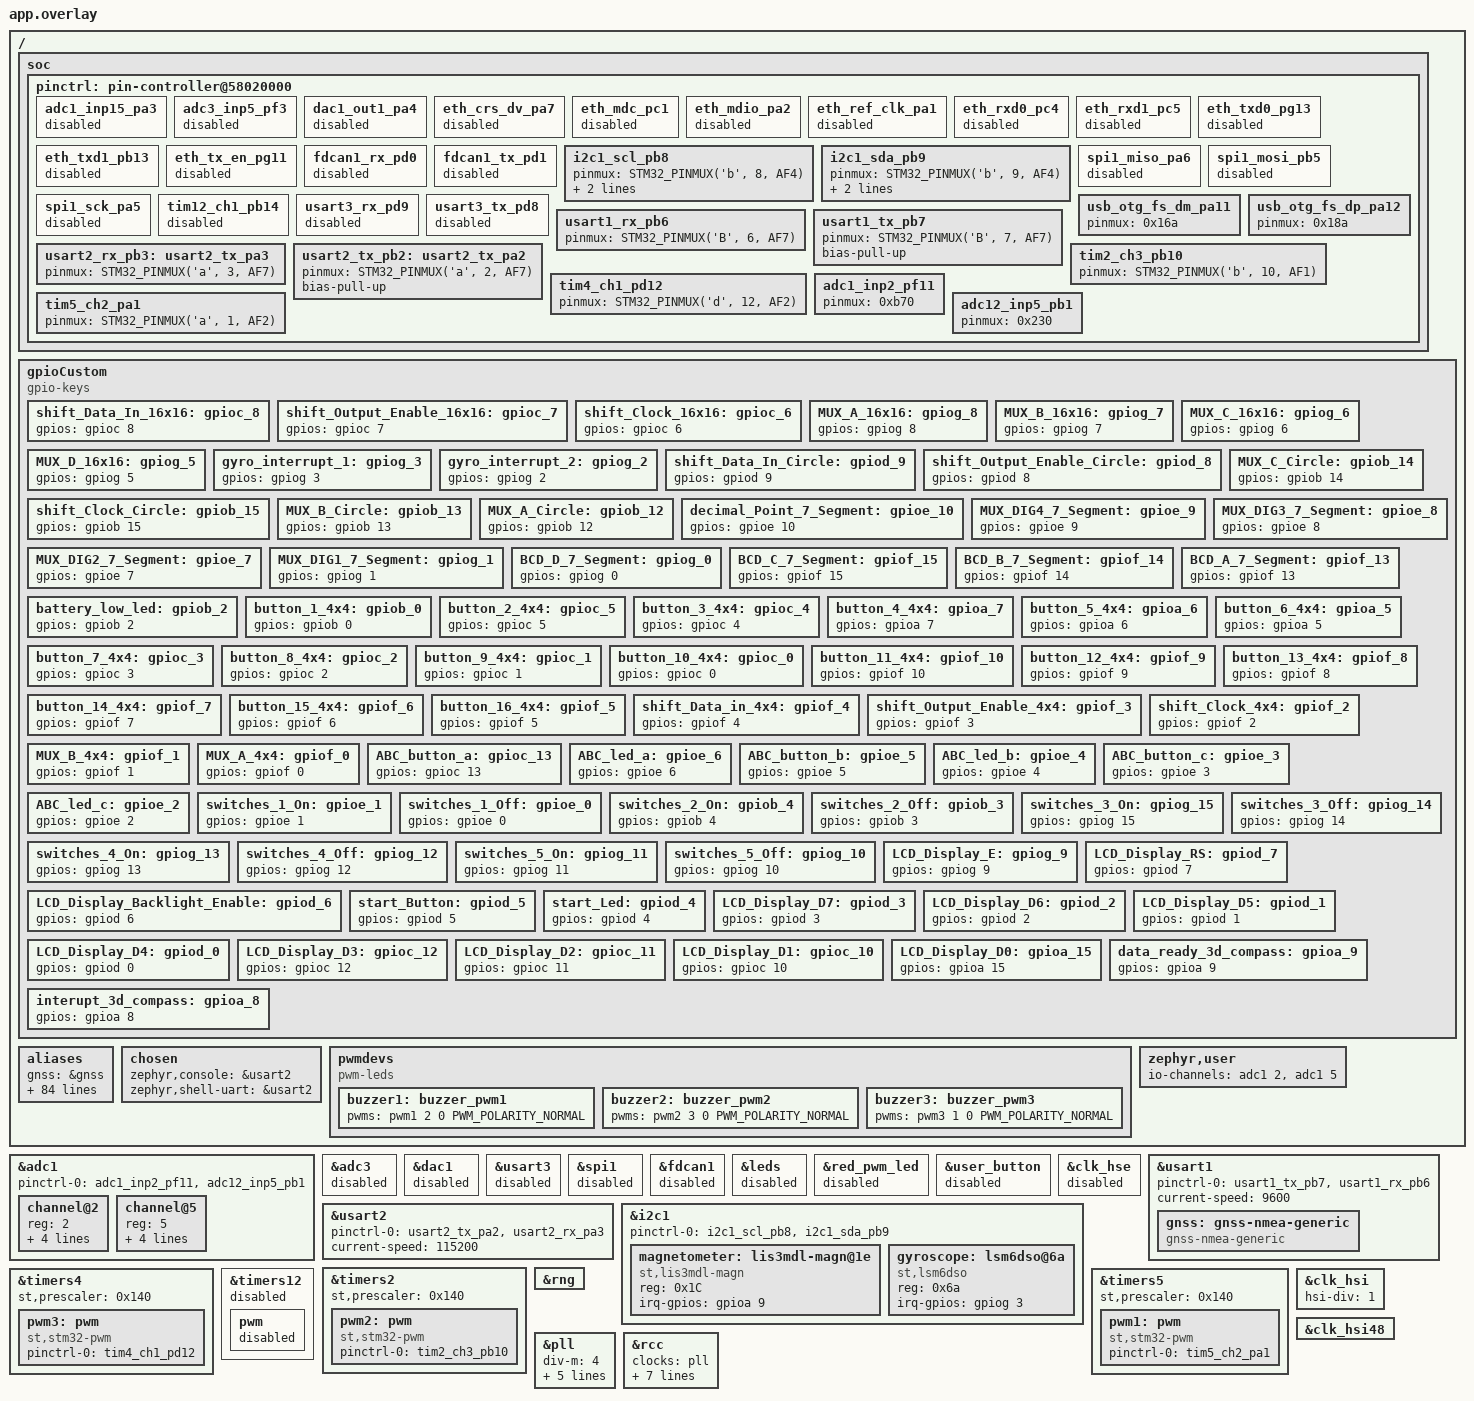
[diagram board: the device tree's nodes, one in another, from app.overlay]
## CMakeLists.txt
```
# SPDX-License-Identifier: Apache-2.0

cmake_minimum_required(VERSION 3.20.0)
find_package(Zephyr REQUIRED HINTS $ENV{ZEPHYR_BASE})
project(blinky)


# Gather source files using wildcards for src directory
file(GLOB SRC_HARDWARE_SOURCES 			"hardware/src/*.c")
file(GLOB SRC_HARDWARECONTROL_SOURCES 	"hardwareControl/src/*.c")
file(GLOB SRC_MAIN_SOURCES 				"main/src/*.c")
file(GLOB SRC_STATES_SOURCES 		"states/src/*.c")

# Add your source files
target_sources(app PRIVATE 
    ${SRC_HARDWARE_SOURCES}
	${SRC_HARDWARECONTROL_SOURCES}
	${SRC_MAIN_SOURCES}
	${SRC_STATES_SOURCES}
)

# Add include directories
target_include_directories(app PRIVATE
	${CMAKE_CURRENT_SOURCE_DIR}/hardware/inc
	${CMAKE_CURRENT_SOURCE_DIR}/hardwareControl/inc
	${CMAKE_CURRENT_SOURCE_DIR}/main/inc
	${CMAKE_CURRENT_SOURCE_DIR}/states/inc
)
```

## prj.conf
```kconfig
CONFIG_GPIO=y
CONFIG_DEBUG_OPTIMIZATIONS=y
CONFIG_SIZE_OPTIMIZATIONS=n
CONFIG_SPEED_OPTIMIZATIONS=n
CONFIG_ENTROPY_GENERATOR=y

CONFIG_STDOUT_CONSOLE=y
CONFIG_CBPRINTF_FP_SUPPORT=y

CONFIG_I2C=y
CONFIG_SENSOR=y
CONFIG_LSM6DSO_TRIGGER_NONE=y
CONFIG_LIS3MDL_ODR="155"

CONFIG_LSM6DSO=y
CONFIG_LSM6DSO_TRIGGER_NONE=y
CONFIG_PWM=y

CONFIG_GNSS=y
CONFIG_GNSS_SATELLITES=y

CONFIG_UART_INTERRUPT_DRIVEN=y
CONFIG_MODEM_MODULES=y

CONFIG_GNSS_SATELLITES=y

# CONFIG_ADC=y
```

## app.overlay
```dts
/ {
	soc {
		pinctrl: pin-controller@58020000 {
			//disable pins
			adc1_inp15_pa3: adc1_inp15_pa3 {
				status = "disabled";
			};
			adc3_inp5_pf3: adc3_inp5_pf3 {
				status = "disabled";
			};
			dac1_out1_pa4: dac1_out1_pa4 {
				status = "disabled";
			};
			eth_crs_dv_pa7: eth_crs_dv_pa7 {
				status = "disabled";
			};
			eth_mdc_pc1: eth_mdc_pc1 {
				status = "disabled";
			};
			eth_mdio_pa2: eth_mdio_pa2 {
				status = "disabled";
			};
			eth_ref_clk_pa1: eth_ref_clk_pa1 {
				status = "disabled";
			};
			eth_rxd0_pc4: eth_rxd0_pc4 {
				status = "disabled";
			};
			eth_rxd1_pc5: eth_rxd1_pc5 {
				status = "disabled";
			};
			eth_txd0_pg13: eth_txd0_pg13 {
				status = "disabled";
			};
			eth_txd1_pb13: eth_txd1_pb13 {
				status = "disabled";
			};
			eth_tx_en_pg11: eth_tx_en_pg11 {
				status = "disabled";
			};
			fdcan1_rx_pd0: fdcan1_rx_pd0 {
				status = "disabled";
			};
			fdcan1_tx_pd1: fdcan1_tx_pd1 {
				status = "disabled";
			};
			i2c1_scl_pb8: i2c1_scl_pb8 {
				status = "okay";
			};
			i2c1_sda_pb9: i2c1_sda_pb9 {
				status = "okay";
			};
			spi1_miso_pa6: spi1_miso_pa6 {
				status = "disabled";
			};
			spi1_mosi_pb5: spi1_mosi_pb5 {
				status = "disabled";
			};
			spi1_sck_pa5: spi1_sck_pa5 {
				status = "disabled";
			};
			tim12_ch1_pb14: tim12_ch1_pb14 {
				status = "disabled";
			};
			usart3_rx_pd9: usart3_rx_pd9 {
				status = "disabled";
			};
			usart3_tx_pd8: usart3_tx_pd8 {
				status = "disabled";
			};

			//enable and configure pins
			usb_otg_fs_dm_pa11: usb_otg_fs_dm_pa11 {
				pinmux = < 0x16a >;
				phandle = < 0x22 >;
				status = "okay";
			};
			usb_otg_fs_dp_pa12: usb_otg_fs_dp_pa12 {
				pinmux = < 0x18a >;
				phandle = < 0x23 >;
				status = "okay";
			};
			usart1_rx_pb6: usart1_rx_pb6 {
				pinmux = <STM32_PINMUX('B', 6, AF7)>;
				status = "okay";
			};
			usart1_tx_pb7: usart1_tx_pb7 {
				pinmux = <STM32_PINMUX('B', 7, AF7)>;
				bias-pull-up;
				status = "okay";
			};
			usart2_rx_pb3: usart2_tx_pa3 {
				pinmux = <STM32_PINMUX('a', 3, AF7)>;
				status = "okay";
			};
			usart2_tx_pb2: usart2_tx_pa2 {
				pinmux = <STM32_PINMUX('a', 2, AF7)>;
				bias-pull-up;
				status = "okay";
			};
			i2c1_scl_pb8: i2c1_scl_pb8 {
				pinmux = <STM32_PINMUX('b', 8, AF4)>;
				bias-pull-up;
				drive-open-drain;
				status = "okay";
				phandle = < 0xb >;
			};
			i2c1_sda_pb9: i2c1_sda_pb9 {
				pinmux = <STM32_PINMUX('b', 9, AF4)>;
				bias-pull-up;
				drive-open-drain;
				status = "okay";
				phandle = < 0xc >;
			};
			tim2_ch3_pb10: tim2_ch3_pb10{
				pinmux = <STM32_PINMUX('b', 10, AF1)>;
				status = "okay";
			};
			tim4_ch1_pd12: tim4_ch1_pd12{
				pinmux = <STM32_PINMUX('d', 12, AF2)>;
				status = "okay";
			};
			tim5_ch2_pa1: tim5_ch2_pa1{
				pinmux = <STM32_PINMUX('a', 1, AF2)>;
				status = "okay";
			};
			adc1_inp2_pf11: adc1_inp2_pf11 {
			pinmux = < 0xb70 >;
			status = "okay";
			};
			adc12_inp5_pb1: adc12_inp5_pb1 {
				pinmux = < 0x230 >;
				status = "okay";
			};
		};
	};

	gpioCustom {
		compatible = "gpio-keys";

		shift_Data_In_16x16: gpioc_8 {
			gpios = <&gpioc 8 GPIO_ACTIVE_HIGH>;
		};
		shift_Output_Enable_16x16: gpioc_7 {
			gpios = <&gpioc 7 GPIO_ACTIVE_HIGH>;
		};
		shift_Clock_16x16: gpioc_6 {
			gpios = <&gpioc 6 GPIO_ACTIVE_HIGH>;
		};
		MUX_A_16x16: gpiog_8 {
			gpios = <&gpiog 8 GPIO_ACTIVE_HIGH>;
		};
		MUX_B_16x16: gpiog_7 {
			gpios = <&gpiog 7 GPIO_ACTIVE_HIGH>;
		};
		MUX_C_16x16: gpiog_6 {
			gpios = <&gpiog 6 GPIO_ACTIVE_HIGH>;
		};
		MUX_D_16x16: gpiog_5 {
			gpios = <&gpiog 5 GPIO_ACTIVE_HIGH>;
		};
		gyro_interrupt_1: gpiog_3 {
			gpios = <&gpiog 3 GPIO_ACTIVE_HIGH>;
		};
		gyro_interrupt_2: gpiog_2 {
			gpios = <&gpiog 2 GPIO_ACTIVE_HIGH>;
		};
		shift_Data_In_Circle: gpiod_9 {
			gpios = <&gpiod 9 GPIO_ACTIVE_HIGH>;
		};
		shift_Output_Enable_Circle: gpiod_8 {
			gpios = <&gpiod 8 GPIO_ACTIVE_HIGH>;
		};
		shift_Clock_Circle: gpiob_15 {
			gpios = <&gpiob 15 GPIO_ACTIVE_HIGH>;
		};
		MUX_C_Circle: gpiob_14 {
			gpios = <&gpiob 14 GPIO_ACTIVE_HIGH>;
		};
		MUX_B_Circle: gpiob_13 {
			gpios = <&gpiob 13 GPIO_ACTIVE_HIGH>;
		};
		MUX_A_Circle: gpiob_12 {
			gpios = <&gpiob 12 GPIO_ACTIVE_HIGH>;
		};
		decimal_Point_7_Segment: gpioe_10 {
			gpios = <&gpioe 10 GPIO_ACTIVE_HIGH>;
		};
		MUX_DIG4_7_Segment: gpioe_9 {
			gpios = <&gpioe 9 GPIO_ACTIVE_HIGH>;
		};
		MUX_DIG3_7_Segment: gpioe_8 {
			gpios = <&gpioe 8 GPIO_ACTIVE_HIGH>;
		};
		MUX_DIG2_7_Segment: gpioe_7 {
			gpios = <&gpioe 7 GPIO_ACTIVE_HIGH>;
		};
		MUX_DIG1_7_Segment: gpiog_1 {
			gpios = <&gpiog 1 GPIO_ACTIVE_HIGH>;
		};
		BCD_D_7_Segment: gpiog_0 {
			gpios = <&gpiog 0 GPIO_ACTIVE_HIGH>;
		};
		BCD_C_7_Segment: gpiof_15 {
			gpios = <&gpiof 15 GPIO_ACTIVE_HIGH>;
		};
		BCD_B_7_Segment: gpiof_14 {
			gpios = <&gpiof 14 GPIO_ACTIVE_HIGH>;
		};
		BCD_A_7_Segment: gpiof_13 {
			gpios = <&gpiof 13 GPIO_ACTIVE_HIGH>;
		};
		battery_low_led: gpiob_2 {
			gpios = <&gpiob 2 GPIO_ACTIVE_HIGH>;
		};
		button_1_4x4: gpiob_0 {
			gpios = <&gpiob 0 GPIO_PULL_UP>;
		};
		button_2_4x4: gpioc_5 {
			gpios = <&gpioc 5 GPIO_PULL_UP>;
		};
		button_3_4x4: gpioc_4 {
			gpios = <&gpioc 4 GPIO_PULL_UP>;
		};
		button_4_4x4: gpioa_7 {
			gpios = <&gpioa 7 GPIO_PULL_UP>;
		};
		button_5_4x4: gpioa_6 {
			gpios = <&gpioa 6 GPIO_PULL_UP>;
		};
		button_6_4x4: gpioa_5 {
			gpios = <&gpioa 5 GPIO_PULL_UP>;
		};
		button_7_4x4: gpioc_3 {
			gpios = <&gpioc 3 GPIO_PULL_UP>;
		};
		button_8_4x4: gpioc_2 {
			gpios = <&gpioc 2 GPIO_PULL_UP>;
		};
		button_9_4x4: gpioc_1 {
			gpios = <&gpioc 1 GPIO_PULL_UP>;
		};
		button_10_4x4: gpioc_0 {
			gpios = <&gpioc 0 GPIO_PULL_UP>;
		};
		button_11_4x4: gpiof_10 {
			gpios = <&gpiof 10 GPIO_PULL_UP>;
		};
		button_12_4x4: gpiof_9 {
			gpios = <&gpiof 9 GPIO_PULL_UP>;
		};
		button_13_4x4: gpiof_8 {
			gpios = <&gpiof 8 GPIO_PULL_UP>;
		};
		button_14_4x4: gpiof_7 {
			gpios = <&gpiof 7 GPIO_PULL_UP>;
		};
		button_15_4x4: gpiof_6 {
			gpios = <&gpiof 6 GPIO_PULL_UP>;
		};
		button_16_4x4: gpiof_5 {
			gpios = <&gpiof 5 GPIO_PULL_UP>;
		};
		shift_Data_in_4x4: gpiof_4 {
			gpios = <&gpiof 4 GPIO_ACTIVE_HIGH>;
		};
		shift_Output_Enable_4x4: gpiof_3 {
			gpios = <&gpiof 3 GPIO_ACTIVE_HIGH>;
		};
		shift_Clock_4x4: gpiof_2 {
			gpios = <&gpiof 2 GPIO_ACTIVE_HIGH>;
		};
		MUX_B_4x4: gpiof_1 {
			gpios = <&gpiof 1 GPIO_ACTIVE_HIGH>;
		};
		MUX_A_4x4: gpiof_0 {
			gpios = <&gpiof 0 GPIO_ACTIVE_HIGH>;
		};
		ABC_button_a: gpioc_13 {
			gpios = <&gpioc 13 GPIO_PULL_UP>;
		};
		ABC_led_a: gpioe_6 {
			gpios = <&gpioe 6 GPIO_ACTIVE_HIGH>;
		};
		ABC_button_b: gpioe_5 {
			gpios = <&gpioe 5 GPIO_PULL_UP>;
		};
		ABC_led_b: gpioe_4 {
			gpios = <&gpioe 4 GPIO_ACTIVE_HIGH>;
		};
		ABC_button_c: gpioe_3 {
			gpios = <&gpioe 3 GPIO_PULL_UP>;
		};
		ABC_led_c: gpioe_2 {
			gpios = <&gpioe 2 GPIO_ACTIVE_HIGH>;
		};
		switches_1_On: gpioe_1 {
			gpios = <&gpioe 1 GPIO_PULL_UP>;
		};
		switches_1_Off: gpioe_0 {
			gpios = <&gpioe 0 GPIO_PULL_UP>;
		};
		switches_2_On: gpiob_4 {
			gpios = <&gpiob 4 GPIO_PULL_UP>;
		};
		switches_2_Off: gpiob_3 {
			gpios = <&gpiob 3 GPIO_PULL_UP>;
		};
		switches_3_On: gpiog_15 {
			gpios = <&gpiog 15 GPIO_PULL_UP>;
		};
		switches_3_Off: gpiog_14 {
			gpios = <&gpiog 14 GPIO_PULL_UP>;
		};
		switches_4_On: gpiog_13 {
			gpios = <&gpiog 13 GPIO_PULL_UP>;
		};
		switches_4_Off: gpiog_12 {
			gpios = <&gpiog 12 GPIO_PULL_UP>;
		};
		switches_5_On: gpiog_11 {
			gpios = <&gpiog 11 GPIO_PULL_UP>;
		};
		switches_5_Off: gpiog_10 {
			gpios = <&gpiog 10 GPIO_PULL_UP>;
		};
		LCD_Display_E: gpiog_9 {
			gpios = <&gpiog 9 GPIO_ACTIVE_HIGH>;
		};
		LCD_Display_RS: gpiod_7 {
			gpios = <&gpiod 7 GPIO_ACTIVE_HIGH>;
		};
		LCD_Display_Backlight_Enable: gpiod_6 {
			gpios = <&gpiod 6 GPIO_ACTIVE_HIGH>;
		};
		start_Button: gpiod_5 {
			gpios = <&gpiod 5 GPIO_PULL_UP>;
		};
		start_Led: gpiod_4 {
			gpios = <&gpiod 4 GPIO_ACTIVE_HIGH>;
		};
		LCD_Display_D7: gpiod_3 {
			gpios = <&gpiod 3 GPIO_ACTIVE_HIGH>;
		};
		LCD_Display_D6: gpiod_2 {
			gpios = <&gpiod 2 GPIO_ACTIVE_HIGH>;
		};
		LCD_Display_D5: gpiod_1 {
			gpios = <&gpiod 1 GPIO_ACTIVE_HIGH>;
		};
		LCD_Display_D4: gpiod_0 {
			gpios = <&gpiod 0 GPIO_ACTIVE_HIGH>;
		};
		LCD_Display_D3: gpioc_12 {
			gpios = <&gpioc 12 GPIO_ACTIVE_HIGH>;
		};
		LCD_Display_D2: gpioc_11 {
			gpios = <&gpioc 11 GPIO_ACTIVE_HIGH>;
		};
		LCD_Display_D1: gpioc_10 {
			gpios = <&gpioc 10 GPIO_ACTIVE_HIGH>;
		};
		LCD_Display_D0: gpioa_15 {
			gpios = <&gpioa 15 GPIO_ACTIVE_HIGH>;
		};
		data_ready_3d_compass: gpioa_9 {
			gpios = <&gpioa 9 GPIO_PULL_UP>;
		};
		interupt_3d_compass: gpioa_8 {
			gpios = <&gpioa 8 GPIO_PULL_UP>;
		};
	};

	aliases {
		gnss = &gnss;
		shiftdatain16x16 = &shift_Data_In_16x16;
		shiftenable16x16 = &shift_Output_Enable_16x16;
		shiftclock16x16 = &shift_Clock_16x16;
		muxa16x16 = &MUX_A_16x16;
		muxb16x16 = &MUX_B_16x16;
		muxc16x16 = &MUX_C_16x16;
		muxd16x16 = &MUX_D_16x16;
		gyrointerrupt1 = &gyro_interrupt_1;
		gyrointerrupt2 = &gyro_interrupt_2;
		shiftdataincircle = &shift_Data_In_Circle;
		shiftoutputenablecircle = &shift_Output_Enable_Circle;
		shiftclockcircle = &shift_Clock_Circle;
		muxacircle = &MUX_A_Circle;
		muxbcircle = &MUX_B_Circle;
		muxccircle = &MUX_C_Circle;
		decimalpoint7segment = &decimal_Point_7_Segment;
		muxdig17segment = &MUX_DIG1_7_Segment;
		muxdig27segment = &MUX_DIG2_7_Segment;
		muxdig37segment = &MUX_DIG3_7_Segment;
		muxdig47segment = &MUX_DIG4_7_Segment;
		bcdd7segment = &BCD_D_7_Segment;
		bcdc7segment = &BCD_C_7_Segment;
		bcdb7segment = &BCD_B_7_Segment;
		bcda7segment = &BCD_A_7_Segment;
		batterylowled = &battery_low_led;		
		button14x4 = &button_1_4x4;
		button24x4 = &button_2_4x4;
		button34x4 = &button_3_4x4;
		button44x4 = &button_4_4x4;
		button54x4 = &button_5_4x4;
		button64x4 = &button_6_4x4;
		button74x4 = &button_7_4x4;
		button84x4 = &button_8_4x4;
		button94x4 = &button_9_4x4;
		button104x4 = &button_10_4x4;
		button114x4 = &button_11_4x4;
		button124x4 = &button_12_4x4;
		button134x4 = &button_13_4x4;
		button144x4 = &button_14_4x4;
		button154x4 = &button_15_4x4;
		button164x4 = &button_16_4x4;
		shiftdatain4x4 = &shift_Data_in_4x4;
		shiftoutputenable4x4 = &shift_Output_Enable_4x4;
		shiftclock4x4 = &shift_Clock_4x4;
		muxa4x4 = &MUX_A_4x4;
		muxb4x4 = &MUX_B_4x4;
		abcbuttona = &ABC_button_a;
		abcleda = &ABC_led_a;
		abcbuttonb = &ABC_button_b;
		abcledb = &ABC_led_b;
		abcbuttonc = &ABC_button_c;
		abcledc = &ABC_led_c;
		switches1on = &switches_1_On;
		switches1off = &switches_1_Off;
		switches2on = &switches_2_On;
		switches2off = &switches_2_Off;
		switches3on = &switches_3_On;
		switches3off = &switches_3_Off;
		switches4on = &switches_4_On;
		switches4off = &switches_4_Off;
		switches5on = &switches_5_On;
		switches5off = &switches_5_Off;
		lcddisplaye = &LCD_Display_E;
		lcddisplayrs = &LCD_Display_RS;
		lcddisplaybacklightenable = &LCD_Display_Backlight_Enable;
		startbutton = &start_Button;
		startled = &start_Led;
		lcddisplayd7 = &LCD_Display_D7;
		lcddisplayd6 = &LCD_Display_D6;
		lcddisplayd5 = &LCD_Display_D5;
		lcddisplayd4 = &LCD_Display_D4;
		lcddisplayd3 = &LCD_Display_D3;
		lcddisplayd2 = &LCD_Display_D2;
		lcddisplayd1 = &LCD_Display_D1;
		lcddisplayd0 = &LCD_Display_D0;
		buzzer1=&buzzer1;
		buzzer2=&buzzer2;
		buzzer3=&buzzer3;
		3dcompassdataready = &data_ready_3d_compass;
		3dcompassintterupt = &interupt_3d_compass;
		magnetometer=&magnetometer;
		gyroscope=&gyroscope;
	};

	 chosen {
		zephyr,console = &usart2;
		zephyr,shell-uart = &usart2;
	};

	pwmdevs {
		compatible = "pwm-leds";
		status = "okay";
		buzzer1: buzzer_pwm1 {
			pwms = 	<&pwm1 2 0 PWM_POLARITY_NORMAL>;
			status = "okay";
		};
		buzzer2: buzzer_pwm2 {
			pwms = 	<&pwm2 3 0 PWM_POLARITY_NORMAL>;
			status = "okay";
		};
		buzzer3: buzzer_pwm3 {
			pwms = 	<&pwm3 1 0 PWM_POLARITY_NORMAL>;
			status = "okay";
		};
	};
};

/ {
	zephyr,user {
		/* adjust channel number according to pinmux in board.dts */
		io-channels = <&adc1 2>, <&adc1 5>;
	};
};

&adc1{
		status = "okay";
		pinctrl-0 = < &adc1_inp2_pf11 &adc12_inp5_pb1>;
		

		#address-cells = <1>;
		#size-cells = <0>;

		channel@2 {
			reg = <2>;
			zephyr,gain = "ADC_GAIN_1";
			zephyr,reference = "ADC_REF_INTERNAL";
			zephyr,acquisition-time = <ADC_ACQ_TIME_DEFAULT>;
			zephyr,resolution = <12>;
		};

		channel@5 {
			reg = <5>;
			zephyr,gain = "ADC_GAIN_1";
			zephyr,reference = "ADC_REF_INTERNAL";
			zephyr,acquisition-time = <ADC_ACQ_TIME_DEFAULT>;
			zephyr,resolution = <12>;
		};
	
};

//disable unused


&adc3{
		status = "disabled";
};

&dac1{
		status = "disabled";
};

&usart3 {
		status = "disabled";
};

&spi1 {
		status = "disabled";
};

&fdcan1{
		status = "disabled";
};

&leds{
		status = "disabled";
};

&red_pwm_led {
		status = "okay";
};

&user_button {
		status = "disabled";
};

&clk_hse {
		status = "disabled";
};

//enable used

&usart1 {
		pinctrl-0 = < &usart1_tx_pb7 &usart1_rx_pb6 >;
		pinctrl-names = "default";
        current-speed = <9600>;
        status = "okay";
        gnss: gnss-nmea-generic {
                compatible = "gnss-nmea-generic";
        };
};

&usart2 {
		pinctrl-0 = < &usart2_tx_pa2 &usart2_rx_pa3 >;
		pinctrl-names = "default";
        current-speed = <115200>;
        status = "okay";
};


&i2c1{
		status = "okay";
		pinctrl-0 = < &i2c1_scl_pb8 &i2c1_sda_pb9 >;

		magnetometer: lis3mdl-magn@1e {
			compatible = "st,lis3mdl-magn";
			reg = <0x1C>;
			irq-gpios = <&gpioa 9 GPIO_ACTIVE_HIGH>;
		};

		gyroscope: lsm6dso@6a {
			compatible = "st,lsm6dso";
			reg = <0x6a>;
			irq-gpios = <&gpiog 3 GPIO_ACTIVE_HIGH>; //the selected pin is wrong. check schematic
		};
};

// &timers1{
// 	status = "okay";
// 	st,prescaler = < 0x140 >; 
// 	pwm1: pwm{
// 		compatible = "st,stm32-pwm";
// 		status = "okay";
// 		#pwm-cells = < 0x3 >;
// 		pinctrl-0 = < &tim1_ch1_pe9>;
// 		pinctrl-names = "default";
// 	};
// };

&timers2{
	status = "okay";
	st,prescaler = < 0x140 >; 
	pwm2: pwm{
		compatible = "st,stm32-pwm";
		status = "okay";
		#pwm-cells = < 0x3 >;
		pinctrl-0 = < &tim2_ch3_pb10>;
		pinctrl-names = "default";
	};
};

&timers4{
	status = "okay";
	st,prescaler = < 0x140 >; 
	pwm3: pwm{
		compatible = "st,stm32-pwm";
		status = "okay";
		#pwm-cells = < 0x3 >;
		pinctrl-0 = < &tim4_ch1_pd12>;
		pinctrl-names = "default";
	};
};

&timers5{
	status = "okay";
	st,prescaler = < 0x140 >; 
	pwm1: pwm{
		compatible = "st,stm32-pwm";
		status = "okay";
		#pwm-cells = < 0x3 >;
		pinctrl-0 = < &tim5_ch2_pa1>;
		pinctrl-names = "default";
	};
};

&timers12{
	status = "disabled";
	pwm{
		status = "disabled";
	};
};

&clk_hsi{
	status = "okay";
	hsi-div = <1>;
};

&clk_hsi48{
	status = "okay";
};

&rng{
	status = "okay";
};

&pll {
	div-m = <4>;
	mul-n = <40>;
	div-p = <2>;
	div-q = <3>;
	div-r = <2>;
	clocks = <&clk_hsi>;
	status = "okay";
};

&rcc {
	clocks = <&pll>;
	clock-frequency = <DT_FREQ_M(320)>;
	d1cpre = < 0x1 >;
	hpre = < 0x2 >;
	d1ppre = < 0x2 >;
	d2ppre1 = < 0x2 >;
	d2ppre2 = < 0x2 >;
	d3ppre = < 0x2 >;
};

&red_pwm_led{
	status = "disabled";
};
```

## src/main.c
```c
/*
 * Copyright (c) 2023 Trackunit Corporation
 *
 * SPDX-License-Identifier: Apache-2.0
 */
#include "statemachine.h"
#include <stdio.h>

int main(void)
{
	startStatemachine();
	printf("A thing\n");
	return 0;
}
```

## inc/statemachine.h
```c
void startStatemachine();
```

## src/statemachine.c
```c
// Includes: own header file, hardware headers, minigame headers, framework headers, system headers (sorted alpabetically)
#include "statemachine.h"

#include "buttonMatrix.h"
#include "buzzers.h"
#include "genericGpio.h"
#include "gps.h"
#include "gyroCompass.h"
#include "ledCircle.h"
#include "ledMatrix.h"
#include "potmeter.h"
#include "sevenSegment.h"

#include "minigame1.h"
#include "minigame2.h"
#include "minigame3.h"
#include "minigame4.h"
#include "minigame5.h"
#include "minigame6.h"
#include "minigame7.h"
#include "minigame8.h"
#include "minigame9.h"
#include "minigame10.h"

#include <zephyr/device.h>
#include <zephyr/drivers/gpio.h>
#include <zephyr/kernel.h>
#include <zephyr/sys/util.h>
#include <zephyr/sys/printk.h>

#include <stdio.h>


// The stack size of all threads
#define STACKSIZE 1024

// Thread priority values (lower value is higher priority)
#define TSTARTBUTTON_PRIORITY 4
#define TGYRO_PRIORITY 4
#define TGPS_PRIORITY 4
#define TBTNMATRIX_OUT_PRIORITY 7
#define TBTNMATRIX_IN_PRIORITY 4
#define TSWITCHES_PRIORITY 4
#define TPOTMETER_PRIORITY 4
#define TBUZZERS_PRIORITY 7
#define TLEDMATRIX_PRIORITY 7
#define TLEDCIRCLE_PRIORITY 7
#define TSEVENSEG_PRIORITY 7
#define TABCBTN_PRIORITY 4

// Thread IDs
extern const k_tid_t tstartbutton_id;
extern const k_tid_t tgyro_id;
extern const k_tid_t tgps_id;
extern const k_tid_t tbtnmatrix_out_id;
extern const k_tid_t tbtnmatrix_in_id;
extern const k_tid_t tswitches_id;
extern const k_tid_t tpotmeter_id;
extern const k_tid_t tbuzzers_id;
extern const k_tid_t tledmatrix_id;
extern const k_tid_t tledcircle_id;
extern const k_tid_t tsevenseg_id;
extern const k_tid_t tabcbtn_id;

// Setup state machine
struct state;
typedef void state_fn(struct state *);

struct state {
	state_fn *next;
	int i;
};

state_fn init_state, walk_state, mg1_state, mg2_state, mg3_state, mg4_state, mg5_state, mg6_state, mg7_state, mg8_state, mg9_state, mg10_state, exit_state;

// State functions
void init_state(struct state *state) {
	printf("Initialization\n");

	// Disable all io threads
	k_thread_suspend(tstartbutton_id);
	k_thread_suspend(tgyro_id);
	k_thread_suspend(tgps_id);
	k_thread_suspend(tbtnmatrix_out_id);
	k_thread_suspend(tbtnmatrix_in_id);
	k_thread_suspend(tswitches_id);
	k_thread_suspend(tpotmeter_id);
	k_thread_suspend(tbuzzers_id);
	k_thread_suspend(tledmatrix_id);
	k_thread_suspend(tledcircle_id);
	k_thread_suspend(tsevenseg_id);
	k_thread_suspend(tabcbtn_id);

	state->next = walk_state;
}

void walk_state(struct state *state) {
	printf("Walking\n");
	state->next = mg1_state;
}

void mg1_state(struct state *state) { // Makes use of button and led
	// Initialise state, enable and disable corresponding threads
	printf("Minigame 1\n");

	// Enable required threads
	//k_thread_resume(tstartbutton_id);
	//k_thread_resume(tgyro_id);
	//k_thread_resume(tledmatrix_id);
	/* Temporarily enabling GPS in this mingame so I can test the driver **************************************/
	k_thread_resume(tgps_id);

	int ret = playMg1();

	// Disable required threads after finishing
	k_thread_suspend(tstartbutton_id);
	k_thread_suspend(tgyro_id);
	k_thread_suspend(tledmatrix_id);
	/* Temporarily enabling GPS in this mingame so I can test the driver **************************************/
	k_thread_suspend(tgps_id);

	state->next = mg2_state;
}

void mg2_state(struct state *state) { // Makes use of gyro and buzzer
	printf("Minigame 2\n");

	// Enable required threads
	k_thread_resume(tstartbutton_id);
	k_thread_resume(tbtnmatrix_in_id);
	k_thread_resume(tbtnmatrix_out_id);
	k_thread_resume(tbuzzers_id);

	int ret = playMg2();

	// Disable required threads after finishing
	k_thread_suspend(tstartbutton_id);
	k_thread_suspend(tbtnmatrix_in_id);
	k_thread_suspend(tbtnmatrix_out_id);
	k_thread_suspend(tbuzzers_id);

	state->next = mg3_state;
}

void mg3_state(struct state *state) { // Makes use of gyro and buzzer
	printf("Minigame 3\n");

	// Enable required threads
	k_thread_resume(tstartbutton_id);
	k_thread_resume(tbtnmatrix_in_id);
	k_thread_resume(tbtnmatrix_out_id);
	k_thread_resume(tbuzzers_id);

	int ret = playMg3();

	// Disable required threads after finishing
	k_thread_suspend(tstartbutton_id);
	k_thread_suspend(tbtnmatrix_in_id);
	k_thread_suspend(tbtnmatrix_out_id);
	k_thread_suspend(tbuzzers_id);

	state->next = mg4_state;
}

void mg4_state(struct state *state) { // Makes use of gyro and buzzer
	printf("Minigame 4\n");

	// Enable required threads
	k_thread_resume(tstartbutton_id);
	k_thread_resume(tbuzzers_id);
	k_thread_resume(tabcbtn_id);

	int ret = playMg4();

	// Disable required threads after finishing
	k_thread_suspend(tstartbutton_id);
	k_thread_suspend(tbuzzers_id);
	k_thread_suspend(tabcbtn_id);

	state->next = mg5_state;
}

void mg5_state(struct state *state) { // Makes use of gyro and buzzer
	printf("Minigame 5\n");

	// Enable required threads
	k_thread_resume(tstartbutton_id);
	k_thread_resume(tbtnmatrix_in_id);
	k_thread_resume(tbtnmatrix_out_id);

	int ret = playMg5();

	// Disable required threads after finishing
	k_thread_suspend(tstartbutton_id);
	k_thread_suspend(tbtnmatrix_in_id);
	k_thread_suspend(tbtnmatrix_out_id);

	state->next = mg6_state;
}

void mg6_state(struct state *state) { // Makes use of gyro and buzzer
	printf("Minigame 6\n");

	// Enable required threads
	k_thread_resume(tstartbutton_id);
	k_thread_resume(tsevenseg_id);
	k_thread_resume(tabcbtn_id);

	int ret = playMg6();

	// Disable required threads after finishing
	k_thread_suspend(tstartbutton_id);
	k_thread_suspend(tsevenseg_id);
	k_thread_suspend(tabcbtn_id);;

	state->next = mg7_state;
}

void mg7_state(struct state *state) { // Makes use of gyro and buzzer
	printf("Minigame 7\n");

	// Enable required threads
	k_thread_resume(tstartbutton_id);
	k_thread_resume(tgyro_id);
	k_thread_resume(tledmatrix_id);

	int ret = playMg7();

	// Disable required threads after finishing
	k_thread_suspend(tstartbutton_id);
	k_thread_suspend(tgyro_id);
	k_thread_suspend(tledmatrix_id);

	state->next = mg8_state;
}

void mg8_state(struct state *state) { // Makes use of gyro and buzzer
	printf("Minigame 8\n");

	// Enable required threads
	k_thread_resume(tstartbutton_id);
	k_thread_resume(tledmatrix_id);
	k_thread_resume(tabcbtn_id);

	int ret = playMg8();

	// Disable required threads after finishing
	k_thread_suspend(tstartbutton_id);
	k_thread_suspend(tledmatrix_id);
	k_thread_suspend(tabcbtn_id);

	state->next = mg9_state;
}

void mg9_state(struct state *state) { // Makes use of gyro and buzzer
	printf("Minigame 9\n");

	// Enable required threads
	k_thread_resume(tstartbutton_id);
	k_thread_resume(tswitches_id);

	int ret = playMg9();

	// Disable required threads after finishing
	k_thread_suspend(tstartbutton_id);
	k_thread_suspend(tswitches_id);

	state->next = mg10_state;
}

void mg10_state(struct state *state) { // Makes use of gyro and buzzer
	printf("Minigame 10\n");

	// Enable required threads
	k_thread_resume(tstartbutton_id);
	k_thread_resume(tbtnmatrix_in_id);
	k_thread_resume(tswitches_id);
	k_thread_resume(tpotmeter_id);
	k_thread_resume(tabcbtn_id);

	int ret = playMg10();

	// Disable required threads after finishing
	k_thread_suspend(tstartbutton_id);
	k_thread_suspend(tbtnmatrix_in_id);
	k_thread_suspend(tswitches_id);
	k_thread_suspend(tpotmeter_id);
	k_thread_suspend(tabcbtn_id);

	state->next = exit_state;
}

void exit_state(struct state *state) {
	printf("Exit state");
	k_thread_suspend(tstartbutton_id);
	k_thread_suspend(tgyro_id);
	k_thread_suspend(tgps_id);
	k_thread_suspend(tbtnmatrix_out_id);
	k_thread_suspend(tbtnmatrix_in_id);
	k_thread_suspend(tswitches_id);
	k_thread_suspend(tpotmeter_id);
	k_thread_suspend(tbuzzers_id);
	k_thread_suspend(tledmatrix_id);
	k_thread_suspend(tledcircle_id);
	k_thread_suspend(tsevenseg_id);
	k_thread_suspend(tabcbtn_id);
	state->next = 0;
}

void startStatemachine() {
	struct state state = {init_state, 0};
	while (state.next) state.next(&state);
}

// Define the threads
// Input threads
K_THREAD_DEFINE(tstartbutton_id, STACKSIZE, tstartbutton, NULL, NULL, NULL, TSTARTBUTTON_PRIORITY, 0,0);
K_THREAD_DEFINE(tgyro_id, STACKSIZE, tgyro, NULL, NULL, NULL, TGYRO_PRIORITY, 0,0);
K_THREAD_DEFINE(tbtnmatrix_in_id, STACKSIZE, tbtnmatrix_in, NULL, NULL, NULL, TBTNMATRIX_IN_PRIORITY, 0, 0);
K_THREAD_DEFINE(tswitches_id, STACKSIZE, tswitches, NULL, NULL, NULL, TSWITCHES_PRIORITY, 0, 0);
K_THREAD_DEFINE(tpotmeter_id, STACKSIZE, tpotmeter, NULL, NULL, NULL, TPOTMETER_PRIORITY, 0, 0);
K_THREAD_DEFINE(tabcbtn_id, STACKSIZE, tabcbtn, NULL, NULL, NULL, TABCBTN_PRIORITY, 0, 0);
// Output threads
K_THREAD_DEFINE(tgps_id, STACKSIZE, tgps, NULL, NULL, NULL, TGPS_PRIORITY, 0, 0);
K_THREAD_DEFINE(tbtnmatrix_out_id, STACKSIZE, tbtnmatrix_out, NULL, NULL, NULL, TBTNMATRIX_OUT_PRIORITY, 0, 0);
K_THREAD_DEFINE(tbuzzers_id, STACKSIZE, tbuzzers, NULL, NULL, NULL, TBUZZERS_PRIORITY, 0, 0);
K_THREAD_DEFINE(tledmatrix_id, STACKSIZE, tledmatrix, NULL, NULL, NULL, TLEDMATRIX_PRIORITY, 0, 0);
K_THREAD_DEFINE(tledcircle_id, STACKSIZE, tledcircle, NULL, NULL, NULL, TLEDCIRCLE_PRIORITY, 0, 0);
K_THREAD_DEFINE(tsevenseg_id, STACKSIZE, tsevenseg, NULL, NULL, NULL, TSEVENSEG_PRIORITY, 0, 0);
```

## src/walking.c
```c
#include "walking.h"

int myFunction() {
	return 0;
}
```
